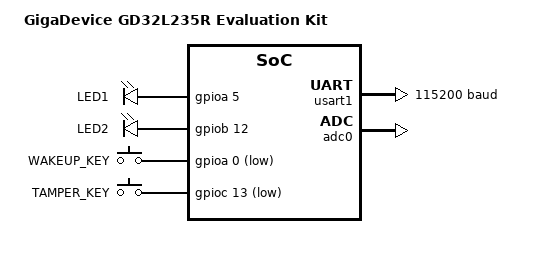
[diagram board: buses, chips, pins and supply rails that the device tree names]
/*
 * SPDX-FileCopyrightText: Copyright The Zephyr Project Contributors
 * SPDX-License-Identifier: Apache-2.0
 */

/dts-v1/;

#include <gd/gd32l23x/gd32l235rb.dtsi>
#include "gd32l235r_eval-pinctrl.dtsi"
#include <zephyr/dt-bindings/input/input-event-codes.h>

/ {
	model = "GigaDevice GD32L235R Evaluation Kit";
	compatible = "gd,gd32l235r-eval";

	chosen {
		zephyr,sram = &sram;
		zephyr,flash = &flash0;
		zephyr,console = &usart1;
		zephyr,shell-uart = &usart1;
		zephyr,flash-controller = &fmc;
	};

	leds {
		compatible = "gpio-leds";

		led1: led1 {
			gpios = <&gpioa 5 GPIO_ACTIVE_HIGH>;
			label = "LED1";
		};

		led2: led2 {
			gpios = <&gpiob 12 GPIO_ACTIVE_HIGH>;
			label = "LED2";
		};
	};

	gpio_keys {
		compatible = "gpio-keys";

		wakeup_key: wakeup_key {
			label = "WAKEUP_KEY";
			gpios = <&gpioa 0 GPIO_ACTIVE_LOW>;
			zephyr,code = <INPUT_KEY_WAKEUP>;
		};

		tamper_key: tamper_key {
			label = "TAMPER_KEY";
			gpios = <&gpioc 13 GPIO_ACTIVE_LOW>;
			zephyr,code = <INPUT_KEY_0>;
		};
	};

	aliases {
		led0 = &led1;
		led1 = &led2;
	};
};

&gpioa {
	status = "okay";
};

&gpiob {
	status = "okay";
};

&gpioc {
	status = "okay";
};

&gpiod {
	status = "okay";
};

&gpiof {
	status = "okay";
};

&usart1 {
	status = "okay";
	current-speed = <115200>;
	pinctrl-0 = <&usart1_default>;
	pinctrl-names = "default";
};

&adc0 {
	status = "okay";
	pinctrl-0 = <&adc0_default>;
	pinctrl-names = "default";
};
